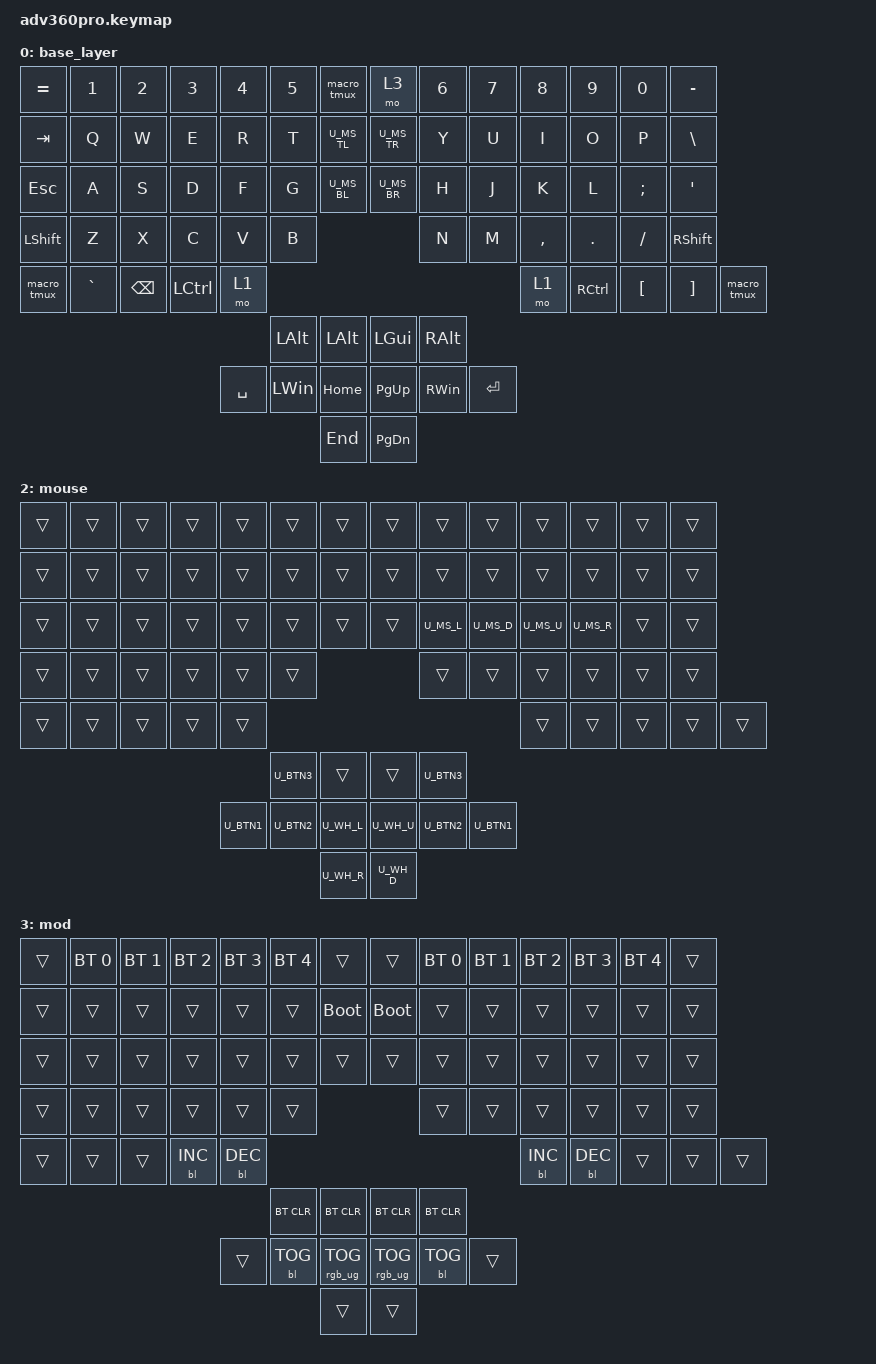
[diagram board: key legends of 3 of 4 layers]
#include <behaviors.dtsi>
#include <dt-bindings/zmk/keys.h>
#include <dt-bindings/zmk/bt.h>
#include <dt-bindings/zmk/outputs.h>
#include <dt-bindings/zmk/rgb.h>
#include <dt-bindings/zmk/backlight.h>

/* definitions for mouse layer */
#include "mouse.dtsi"


#define ___ &trans

#define QWERTY 0
#define ao 1
#define MS 2
#define MOD 3

/ {
    /* remove unused keys from layout and move thumb cluster to bottom */
    chosen {
        zmk,matrix_transform = &urobs_transform;
    };
    behaviors {
        #include "macros.dtsi"
    };

    keymap {
        compatible = "zmk,keymap";

        base_layer {
            bindings = <
&kp EQUAL &kp N1    &kp N2    &kp N3    &kp N4    &kp N5    &macro_tmux    &mo 3     &kp N6     &kp N7    &kp N8        &kp N9    &kp N0    &kp MINUS
&kp TAB   &kp Q     &kp W     &kp E     &kp R     &kp T     U_MS_TL        U_MS_TR   &kp Y      &kp U     &kp I         &kp O     &kp P     &kp BSLH
&kp ESC   &kp A     &kp S     &kp D     &kp F     &kp G     U_MS_BL        U_MS_BR   &kp H      &kp J     &kp K         &kp L     &kp SEMI  &kp SQT
&kp LSHFT &kp Z     &kp X     &kp C     &kp V     &kp B                              &kp N      &kp M     &kp COMMA     &kp DOT   &kp FSLH  &kp RSHFT
&macro_tmux     &kp GRAVE &kp BSPC  &kp LCTRL &mo 1                                                   &mo 1     &kp RCTRL     &kp LBKT  &kp RBKT  &macro_tmux
                                                  &kp LALT  &kp LALT       &kp LGUI  &kp RALT
                                        &kp SPACE  &kp LWIN &kp HOME       &kp PG_UP &kp RWIN  &kp RETURN
                                                            &kp END        &kp PG_DN

            >;
        };

        layer_ao {
            bindings = <
&kp EQUAL   &kp F1      &kp F2        &kp F3         &kp F4          &kp F5    &trans            &mo 3      &kp F6     &kp F7              &kp F8            &kp F9          &kp F10         &kp MINUS
&kp TAB     &kp Q   &macro_dw         &kp END        &kp R           U_WH_U      U_MS_TL          U_MS_TR  &kp C_VOL_DN   &kp C_PREV          &kp C_PLAY_PAUSE  &kp C_NEXT      &kp C_VOL_UP    &kp BSLH
&kp ESC     &kp HOME    &macro_dwfw   &macro_drw     &macro_fw       U_WH_D      U_MS_BL          U_MS_BR      &kp LEFT   &kp DOWN_ARROW      &kp UP            &kp RIGHT       &kp KP_PLUS     &kp SQT
&kp LSHFT   &macro_tws  &macro_dfw    &macro_lwsp    &macro_rwsp     &macro_bw                                  U_MS_L     U_MS_D              U_MS_U            U_MS_R          &kp FSLH        &kp RSHFT
&macro_tmux       &kp GRAVE   &kp DEL  &kp LCTRL      &mo 1                                                             &mo 1               &kp RCTRL         &kp KP_DOT      &kp RBKT        &macro_tmux
                                                &kp LALT &macro_tv    &macro_tblk  &kp RALT
                                        U_BTN2  &kp LWIN &kp HOME  &kp PG_UP  &kp RWIN  U_BTN1
                                                            &kp END        &kp PG_DN
>;
        };

        mouse {
            bindings = <
___       ___       ___       ___       ___       ___       ___            ___       ___       ___       ___       ___       ___       ___
___       ___       ___       ___       ___       ___       ___            ___       ___       ___       ___       ___       ___       ___
___       ___       ___       ___       ___       ___       ___            ___       U_MS_L       U_MS_D       U_MS_U       U_MS_R       ___       ___
___       ___       ___       ___       ___       ___                                ___       ___       ___       ___       ___       ___
___       ___       ___       ___       ___                                          ___       ___       ___       ___       ___
                                                  U_BTN3    ___            ___       U_BTN3
                                        U_BTN1    U_BTN2    U_WH_L         U_WH_U    U_BTN2    U_BTN1
                                                            U_WH_R         U_WH_D
            >;
        };

        mod {
            bindings = <
___       &bt BT_SEL 0 &bt BT_SEL 1 &bt BT_SEL 2 &bt BT_SEL 3 &bt BT_SEL 4 ___              ___         &bt BT_SEL 0 &bt BT_SEL 1     &bt BT_SEL 2 &bt BT_SEL 3 &bt BT_SEL 4 ___
___       ___          ___          ___          ___          ___          &bootloader      &bootloader ___          ___              ___          ___          ___          ___
___       ___          ___          ___          ___          ___          ___              ___         ___          ___              ___          ___          ___          ___
___       ___          ___          ___          ___          ___                                       ___          ___              ___          ___          ___          ___
___       ___          ___          &bl BL_INC   &bl BL_DEC                                                          &bl BL_INC       &bl BL_DEC   ___          ___          ___
                                                              &bt BT_CLR   &bt BT_CLR       &bt BT_CLR  &bt BT_CLR
                                                 ___          &bl BL_TOG   &rgb_ug RGB_TOG              &rgb_ug RGB_TOG         &bl BL_TOG   ___
                                                                           ___              ___
            >;
        };


    };

};

